# DSS_DISPC register map
Vendor: Texas Instruments
Registers are 32-bit, read-write, no defined reset value unless marked. A register's access mark holds for its fields unless they carry their own. Offsets are as the file gives them; [hi:lo] are bit positions; 'fields as' and 'values as' point back to an identical list.

## DSS_DISPC (part 2 of 2)
0x00 DISPC_REVISION ro — This register contains the IP revision code.
  [7:0] REV — IP revision [[br]][7:4] Major revision [[br]][3:0] Minor revision
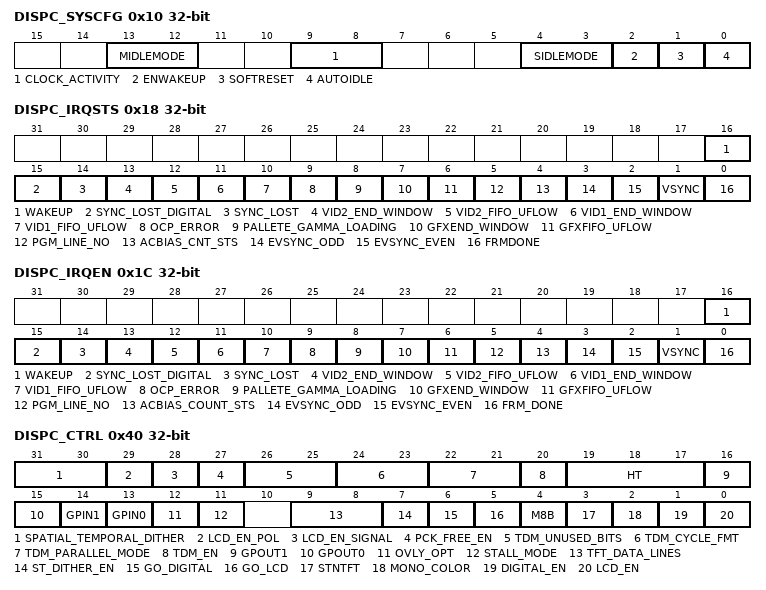
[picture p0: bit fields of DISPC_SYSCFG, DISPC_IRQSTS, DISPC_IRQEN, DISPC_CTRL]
0x10 DISPC_SYSCFG — This register allows the control of various parameters of the interconnect interface
  [13:12] MIDLEMODE — Master interface power management, standby/waitcontrol
    3=en_4_0x3 (3); 2=en_3_0x2 (MStandby is asserted based on the internal activity of the module); 1=en_2_0x1 (MStandby is never asserted); 0=en_1_0x0 (MStandby is asserted only when the module is disabled)
  [9:8] CLOCK_ACTIVITY — Clock activity during wakeup mode period
    3=en_4_0x3 (Interface and functional clocks are maintained during wakeup period); 2=en_3_0x2 (Interface clocks can be switched off and functional clocks are maintained during wakeup period); 1=en_2_0x1 (Functional clocks can be switched off and interface clocks are maintained during wakeup period); 0=en_1_0x0 (interface and functional clocks can be switched off.)
  [4:3] SIDLEMODE — Slave interface power management, idle req/ack control
    3=en_4_0x3 (Reserved); 2=en_3_0x2 (Idle request is acknowledged based on the internal activity of the module); 1=en_2_0x1 (An idle request is never acknowledged); 0=en_1_0x0 (An idle request is acknowledged unconditionally)
  [2] ENWAKEUP — Wakeup feature control
    1=en_2_0x1 (Wakeup is enabled); 0=en_1_0x0 (Wakeup is disabled)
  [1] SOFTRESET — Software reset. [[br]]Set this bit to 1 to trigger a module reset. [[br]]The bit is automatically reset by the hardware. [[br]]During reads, it always returns
    1=en_2_0x1 (The module is reset.); 0=en_1_0x0 (Normal mode)
  [0] AUTOIDLE — Internal interface clock gating strategy
    1=en_2_0x1 (Automatic L3 and L4 interface clock gating strategy is applied based on interface activity); 0=en_1_0x0 (Interface clock is free-running)
0x14 DISPC_SYSSTS ro — This register provides status information about the module, excluding interrupt status information.
  [0] RESETDONE — Internal reset monitoring
    1=en_2_0x1 (Reset complete); 0=en_1_0x0 (Internal module reset is ongoing)
0x18 DISPC_IRQSTS — This register regroups all the status of module internal events that generate an interrupt. A write of 1 to a given bit resets the bit
  [16] WAKEUP
    1=en_4_0x1 (Wakeup is true (pending)); 1=en_3_0x1 (Wakeup status bit reset); 0=en_2_0x0 (Wakeup status bit unchanged); 0=en_1_0x0 (Wakeup is false)
  [15] SYNC_LOST_DIGITAL
    1=en_4_0x1 (SyncLostDigital is true (pending)); 1=en_3_0x1 (SyncLostDigital status bit reset); 0=en_2_0x0 (SyncLostDigital status bit unchanged); 0=en_1_0x0 (SyncLostDigital is false)
  [14] SYNC_LOST
    1=en_4_0x1 (SyncLost is true (pending)); 1=en_3_0x1 (SyncLost status bit reset); 0=en_2_0x0 (SyncLost status bit unchanged); 0=en_1_0x0 (SyncLost is false)
  [13] VID2_END_WINDOW
    1=en_4_0x1 (Vid2EndWindow status bit reset); 1=en_3_0x1 (Vid2EndWindow is true (pending)); 0=en_2_0x0 (Vid2EndWindow status bit unchanged); 0=en_1_0x0 (Vid2EndWindow is false)
  [12] VID2_FIFO_UFLOW — Vid2FIFOUnderflow
    1=en_4_0x1 (Vid2FIFOUnderflow is true (pending)); 1=en_3_0x1 (Vid2FIFOUnderflow status bit reset); 0=en_2_0x0 (Vid2FIFOUnderflow status bit unchanged); 0=en_1_0x0 (Vid2FIFOUnderflow)
  [11] VID1_END_WINDOW
    1=en_4_0x1 (Vid1EndWindow status bit reset); 1=en_3_0x1 (Vid1EndWindow is true (pending).); 0=en_2_0x0 (Vid1EndWindow is false); 0=en_1_0x0 (Vid1EndWindow status bit unchanged)
  [10] VID1_FIFO_UFLOW — Vid1FIFOUnderflow
    1=en_4_0x1 (Vid1FIFOUnderflow status bit reset); 1=en_3_0x1 (Vid1FIFOUnderflow is true (pending).); 0=en_2_0x0 (Vid1FIFOUnderflow status bit unchanged); 0=en_1_0x0 (Vid1FIFOUnderflow is false)
  [9] OCP_ERROR
    1=en_4_0x1 (OCPError status bit reset); 1=en_3_0x1 (OCPError is true (pending).); 0=en_2_0x0 (OCPError is false); 0=en_1_0x0 (OCPError status bit unchanged)
  [8] PALLETE_GAMMA_LOADING — PaletteGammaLoading
    1=en_4_0x1 (PaletteGammaLoading is true (pending)); 1=en_3_0x1 (PaletteGammaLoading status bit reset); 0=en_2_0x0 (PaletteGammaLoading is False); 0=en_1_0x0 (PaletteGammaLoading status bit unchanged)
  [7] GFXEND_WINDOW
    1=en_4_0x1 (GfxEndWindow status bit reset); 1=en_3_0x1 (GfxEndWindow is true (pending).); 0=en_2_0x0 (GfxEndWindow is false.); 0=en_1_0x0 (GfxEndWindow status bit unchanged)
  [6] GFXFIFO_UFLOW — GfxFIFOUnderflow
    1=en_4_0x1 (GfxFIFOUnderflow status bit reset); 1=en_3_0x1 (GfxFIFOUnderflow is true (pending)); 0=en_2_0x0 (GfxFIFOUnderflow is false); 0=en_1_0x0 (GfxFIFOUnderflow status bit unchanged)
  [5] PGM_LINE_NO — ProgrammedLineNumber
    1=en_4_0x1 (ProgrammedLineNumber is true (pending)); 1=en_3_0x1 (ProgrammedLineNumber status bit reset); 0=en_2_0x0 (ProgrammedLineNumber is false); 0=en_1_0x0 (ProgrammedLineNumber status bit unchanged)
  [4] ACBIAS_CNT_STS — ACBiasCountStatus
    1=en_4_0x1 (ACBiasCountStatus is true (pending)); 1=en_3_0x1 (ACBiasCountStatus status bit reset); 0=en_2_0x0 (ACBiasCountStatus is false.); 0=en_1_0x0 (ACBiasCountStatus status bit unchanged)
  [3] EVSYNC_ODD
    1=en_4_0x1 (EVSYNC_ODD is true (pending)); 1=en_3_0x1 (EVSYNC_ODD status bit reset); 0=en_2_0x0 (EVSYNC_ODD status bit unchanged); 0=en_1_0x0 (EVSYNC_ODD is false)
  [2] EVSYNC_EVEN
    1=en_4_0x1 (EVSYNC_EVEN status bit reset); 1=en_3_0x1 (EVSYNC_EVEN is true (pending)); 0=en_2_0x0 (EVSYNC_EVEN is false.); 0=en_1_0x0 (EVSYNC_EVEN status bit unchanged)
  [1] VSYNC
    1=en_4_0x1 (VSYNC is true (pending)); 1=en_3_0x1 (VSYNC status bit reset); 0=en_2_0x0 (VSYNC is false); 0=en_1_0x0 (VSYNC status bit unchanged)
  [0] FRMDONE — FrameDone
    1=en_4_0x1 (FrameDone status bit reset); 1=en_3_0x1 (FrameDone is true (pending).); 0=en_2_0x0 (FrameDone is false); 0=en_1_0x0 (FrameDone status bit unchanged)
0x1C DISPC_IRQEN — This register allows the masking/unmasking of module internal interrupt sources, on an event-by-event basis.
  [16] WAKEUP — Wakeup mask
    1=en_2_0x1 (Wakeup is masked); 0=en_1_0x0 (Wakeup is masked)
  [15] SYNC_LOST_DIGITAL
    1=en_2_0x1 (SyncLostDigital generates an interrupt when it occurs); 0=en_1_0x0 (SyncLostDigital is masked)
  [14] SYNC_LOST
    1=en_2_0x1 (SyncLost is masked); 0=en_1_0x0 (SyncLost is masked)
  [13] VID2_END_WINDOW
    1=en_2_0x1 (Vid2EndWindow generates an interrupt when it occurs); 0=en_1_0x0 (Vid2EndWindow is masked)
  [12] VID2_FIFO_UFLOW — Vid2FIFOUnderflow
    1=en_2_0x1 (Vid2FIFOUnderflow generates an interrupt when it occurs); 0=en_1_0x0 (Vid2FIFOUnderflow is masked)
  [11] VID1_END_WINDOW — EndVid1Window
    1=en_2_0x1 (EndVid1Window is masked); 0=en_1_0x0 (EndVid1Window is masked)
  [10] VID1_FIFO_UFLOW — Vid1FIFOUnderflow
    1=en_2_0x1 (Vid1FIFOUnderflow generates an interrupt when it occurs); 0=en_1_0x0 (Vid1FIFOUnderflow is masked)
  [9] OCP_ERROR
    1=en_2_0x1 (OCPError generates an interrupt when it occurs); 0=en_1_0x0 (OCPError)
  [8] PALLETE_GAMMA_LOADING — PaletteGammaMask
    1=en_2_0x1 (PaletteGammaMask generates an interrupt when it occurs); 0=en_1_0x0 (PaletteGammaMask is masked)
  [7] GFXEND_WINDOW
    1=en_2_0x1 (GfxEndWindow generates an interrupt when it occurs); 0=en_1_0x0 (GfxEndWindow is masked)
  [6] GFXFIFO_UFLOW — GfxFIFOUnderflow
    1=en_2_0x1 (GfxFIFOUnderflow generates an interrupt when it occurs); 0=en_1_0x0 (GfxFIFOUnderflow is masked)
  [5] PGM_LINE_NO — ProgrammedLineNumber
    1=en_2_0x1 (ProgrammedLineNumber generates an interrupt when it occurs); 0=en_1_0x0 (ProgrammedLineNumber is masked.)
  [4] ACBIAS_COUNT_STS — ACBiasCountStatus
    1=en_2_0x1 (ACBiasCountStatus generates an interrupt when it occurs.); 0=en_1_0x0 (ACBiasCountStatus is masked)
  [3] EVSYNC_ODD
    1=en_2_0x1 (EVSYNC_ODD generates an interrupt when it occurs); 0=en_1_0x0 (EVSYNC_ODD is masked)
  [2] EVSYNC_EVEN
    1=en_2_0x1 (EVSYNC_EVEN generates an interrupt when it occurs); 0=en_1_0x0 (EVSYNC_EVEN is masked)
  [1] VSYNC
    1=en_2_0x1 (VSYNC generates an interrupt when it occurs.); 0=en_1_0x0 (VSYNC is masked)
  [0] FRM_DONE — FrameMask
    1=en_2_0x1 (FrameMask generates an interrupt when it occurs); 0=en_1_0x0 (FrameMask is masked)
0x40 DISPC_CTRL access per field — The control register configures the display controller module
  [31:30] SPATIAL_TEMPORAL_DITHER rw — Spatial/Temporal dithering number of frames
    3=en_4_0x3 (Reserved); 2=en_3_0x2 (Spatial and temporal over four frames); 1=en_2_0x1 (Spatial and temporal over two frames); 0=en_1_0x0 (Spatial only)
  [29] LCD_EN_POL rw — LCD Enable Signal Polarity
    1=en_2_0x1 (Active high); 0=en_1_0x0 (Active low)
  [28] LCD_EN_SIGNAL rw — LCD Enable Signal: LCD interface active/inactive
    1=en_2_0x1 (Signal enabled); 0=en_1_0x0 (Signal disabled)
  [27] PCK_FREE_EN rw — Pixel clock free-running enabled/disabled
    1=en_2_0x1 (Clock enabled); 0=en_1_0x0 (Clock disabled)
  [26:25] TDM_UNUSED_BITS rw — State of unused bits (TDM mode only)
    3=en_4_0x3 (Reserved); 2=en_3_0x2 (Unchanged from previous state); 1=en_2_0x1 (High level (1)); 0=en_1_0x0 (Low level (0))
  [24:23] TDM_CYCLE_FMT rw — Cycle format (TDM mode only)
    3=en_4_0x3 (3 cycles for 2 pixels); 2=en_3_0x2 (3 cycles for 1 pixel); 1=en_2_0x1 (2 cycles for 1 pixel); 0=en_1_0x0 (1 cycle for 1 pixel)
  [22:21] TDM_PARALLEL_MODE rw — Output Interface width (TDM mode only)
    3=en_4_0x3 (16-bit parallel output interface selected); 2=en_3_0x2 (12-bit parallel output interface selected); 1=en_2_0x1 (9-bit parallel output interface selected); 0=en_1_0x0 (8-bit parallel output interface selected)
  [20] TDM_EN rw — Enable the multiple cycle format (TDM mode used only for Active Matrix mode with the RFBI enable bit off).
    1=en_2_0x1 (TDM enabled); 0=en_1_0x0 (TDM disabled)
  [19:17] HT rw — Hold Time for digital output WR: EVSYNC Encoded value (from 0 to 7) holds time for digital output. [[br]]The data will be held for (HT + 1) external digital clock periods.
  [16] GPOUT1 rw — General Purpose Output Signal
    1=en_2_0x1 (The GPout1 is set); 0=en_1_0x0 (The GPout1 is reset.)
  [15] GPOUT0 rw — General Purpose Output Signal
    1=en_2_0x1 (The GPout0 is set); 0=en_1_0x0 (The GPout0 is reset)
  [14] GPIN1 ro — General Purpose Input Signal
    1=en_2_0x1 (The GPin1 has been set); 0=en_1_0x0 (The GPin1 has been reset)
  [13] GPIN0 ro — General Purpose Input Signal
    1=en_2_0x1 (The GPin0 has been set); 0=en_1_0x0 (The GPin0 has been reset)
  [12] OVLY_OPT rw — Overlay Optimization (available when graphics format is NOT is 1, 2, and [[br]]4-BPP)
    1=en_2_0x1 (Graphics data below video1 window not fetched from memory.); 0=en_1_0x0 (Graphics data below video1 window fetched from memory or no overlap between graphics and video1 windows)
  [11] STALL_MODE rw — Stall mode for the LCD output
    1=en_2_0x1 (Stall mode selected. The Display Controller sends the data without considering the VSYNC/HSYNC. The LCD output is disabled at the end of the transfer of the frame. The S/W has to re-enable the LCD output to generate a new frame. The stall mode is used in RFBI command modes); 0=en_1_0x0 (Normal mode selected)
  [9:8] TFT_DATA_LINES rw — Number of lines of the LCD interface
    3=en_4_0x3 (24-bit output aligned on the LSB of the pixel data interface); 2=en_3_0x2 (18-bit output aligned on the LSB of the pixel data interface); 1=en_2_0x1 (16-bit output aligned on the LSB of the pixel data interface); 0=en_1_0x0 (12-bit output aligned on the LSB of the pixel data interface)
  [7] ST_DITHER_EN rw — Spatial temporal dithering enable
    1=en_2_0x1 (Spatial/temporal dithering logic enabled); 0=en_1_0x0 (Spatial/temporal dithering logic disabled)
  [6] GO_DIGITAL rw — Digital GO Command
    1=en_2_0x1 (Users have finished programming the shadow registers of the pipeline(s) associated with the digital output and the hardware can update the internal registers at the external VSYNC); 0=en_1_0x0 (The hardware has finished updating the internal shadow registers of the pipeline(s) associated with the digital output using the user values. The hardware resets the bit when the update is completed)
  [5] GO_LCD rw — LCD GO Command
    1=en_2_0x1 (Users have finished programming the shadow registers of the pipeline(s) associated with the LCD output and the hardware can update the internal registers at the VFP start period.); 0=en_1_0x0 (The hardware has finished updating the internal shadow registers of the pipeline(s) connected to the LCD output using the user values. The hardware resets the bit when the update is completed)
  [4] M8B rw — Mono [[br]]8-bit mode
    1=en_2_0x1 (Pixel data [7:0] is used to output eight pixel values to the panel each pixel clock transition (only in Passive Mono 8-bit mode)); 0=en_1_0x0 (Pixel data [3:0] is used to output four pixel values to the panel at each pixel clock transition (only in Passive Mono 8-bit mode))
  [3] STNTFT rw — LCD display type
    1=en_2_0x1 (Active Matrix display operation enabled. Passive Matrix Dither logic and output FIFO bypassed); 0=en_1_0x0 (Passive or Passive Matrix display operation enabled. Passive Matrix dither logic enabled)
  [2] MONO_COLOR rw — Monochrome/Color
    1=en_2_0x1 (Monochrome operation enabled (Passive Matrix mode only)); 0=en_1_0x0 (Color operation enabled (Passive Matrix mode only))
  [1] DIGITAL_EN rw — Digital enable
    1=en_2_0x1 (Digital output enabled); 0=en_1_0x0 (Digital output disabled (at the end of the current field if interlace output when the bit is reset))
  [0] LCD_EN rw — LCD enable
    1=en_2_0x1 (LCD output disabled (at the end of the frame when the bit is reset)); 0=en_1_0x0 (LCD output disabled (at the end of the frame when the bit is reset))
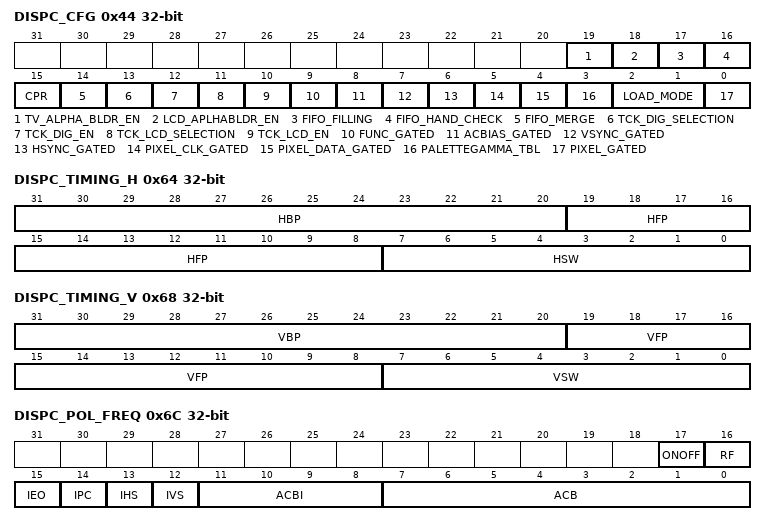
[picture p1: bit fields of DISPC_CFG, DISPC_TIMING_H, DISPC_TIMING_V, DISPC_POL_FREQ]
0x44 DISPC_CFG — This control register configures the display controller module. Shadow register, updated on VFP start period or EVSYNC
  [19] TV_ALPHA_BLDR_EN — Selects the alpha blender (TV output)
    1=en_2_0x1 (The alpha blender is enabled); 0=en_1_0x0 (Alpha blender is disabled)
  [18] LCD_APLHABLDR_EN — Selects the alpha blender (LCD output)
    1=en_2_0x1 (The alpha blender is enabled); 0=en_1_0x0 (Alpha blender is disabled.)
  [17] FIFO_FILLING — Controls if the FIFO are refilled only when the LOW threshold is reached or if all FIFO are refilled when at least one of them reaches the LOW threshold.
    1=en_2_0x1 (All FIFOs are refilled up to high threshold when at least one of them reaches the LOW threshold. (only active FIFOs should be considered and when reaching the end of the frame the FIFO goes to empty condition so no need to fill it again)); 0=en_1_0x0 (Each FIFO is refilled when it reaches LOW threshold)
  [16] FIFO_HAND_CHECK — Controls the handshake between FIFO and RFBI STALL to prevent from underflow. [[br]]The bit should be set to 0 when the module is not in STALL mode
    1=en_2_0x1 (The STALL signal from RFBI is used in combination with the FIFO fullness information to provide data to the RFBI module only when it does not generated FIFO underflow.); 0=en_1_0x0 (Only the STALL signal from RFBI is used regardless of the FIFO fullness information to provide data to the RFBI module)
  [15] CPR — Color phase rotation control wr: VFP
    1=en_2_0x1 (Color phase rotation enabled); 0=en_1_0x0 (Color phase rotation disabled)
  [14] FIFO_MERGE — FIFO merge control
    1=en_2_0x1 (FIFO merge enabled All the FIFOS are merged into a single one to be used by the single active pipeline); 0=en_1_0x0 (FIFO merge disabled Each FIFO is dedicated to one pipeline)
  [13] TCK_DIG_SELECTION — Transparency color key selection (digital output)
    1=en_2_0x1 (Video source transparency color key selected in normal mode); 0=en_1_0x0 (Graphics destination transparency color key selected in normal mode or graphics source transparency color key selected in alpha mode)
  [12] TCK_DIG_EN — Transparency color key enabled (digital output)
    1=en_2_0x1 (Enable the transparency color key for digital output); 0=en_1_0x0 (Disable the transparency color key for digital output)
  [11] TCK_LCD_SELECTION — Transparency color key selection (LCD output)
    values as TCK_DIG_SELECTION
  [10] TCK_LCD_EN — Transparency color key enabled (LCD output)
    1=en_2_0x1 (Enable the transparency color key for the LCD); 0=en_1_0x0 (Disable the transparency color key for the LCD)
  [9] FUNC_GATED — Functional clocks gated enabled
    1=en_2_0x1 (Functional clocks gated enabled); 0=en_1_0x0 (Functional clocks gated disabled)
  [8] ACBIAS_GATED — ACBias Gated Enabled
    1=en_2_0x1 (ACBias Gated Enabled); 0=en_1_0x0 (ACBias Gated Disabled)
  [7] VSYNC_GATED — VSYNC Gated Enabled
    1=en_2_0x1 (VSYNC Gated Enabled); 0=en_1_0x0 (VSYNC Gated Disabled)
  [6] HSYNC_GATED — HSYNC Gated Enabled
    1=en_2_0x1 (HSYNC Gated Enabled); 0=en_1_0x0 (HSYNC Gated Disabled)
  [5] PIXEL_CLK_GATED — Pixel Clock Gated Enabled
    1=en_2_0x1 (Pixel Clock Gated Enabled); 0=en_1_0x0 (Pixel Clock Gated Disabled)
  [4] PIXEL_DATA_GATED — Pixel Data Gated Enabled
    1=en_2_0x1 (Pixel Data Gated Enabled); 0=en_1_0x0 (Pixel Data Gated Disabled)
  [3] PALETTEGAMMA_TBL — Palette/Gamma Table selection
    1=en_2_0x1 (LUT used as gamma table (only if graphics format is NOT BITMAP1, 2, 4, and 8 or no graphics window present)); 0=en_1_0x0 (LUT used as palette (only if graphics format is BITMAP1, 2, 4, and 8))
  [2:1] LOAD_MODE — Loading Mode for the Palette/Gamma Table
    3=en_4_0x3 (Palette/Gamma Table and frame data loaded on first frame then switch to 10 (H/W)); 2=en_3_0x2 (Frame data only loaded every frame); 1=en_2_0x1 (Palette/Gamma Table to be loaded. Users set the bit when the palette/gamma table has to be loaded. H/W resets the bit when table has been loaded. (DISPC_GFX_ATTRIBUTES. GfxEnable has to be set to 1)); 0=en_1_0x0 (Palette/Gamma Table and data are loaded every frame)
  [0] PIXEL_GATED — Pixel Gated Enable (only for Active Matrix Display)
    1=en_2_0x1 (Pixel clock only toggles when there is valid data to display. (only in Active Matrix mode)); 0=en_1_0x0 (Pixel Gated Enable (only for Active Matrix Display))
0x4C DISPC_DEFAULT_COLOR_0 access not given
0x50 DISPC_DEFAULT_COLOR_1 access not given
0x54 DISPC_TRANS_COLOR_0 access not given
0x58 DISPC_TRANS_COLOR_1 access not given
0x5C DISPC_LINE_STS ro — The control register indicates the current LCD panel display line number
  [10:0] LINE_NUMBER — Current LCD panel line number Current display line number. [[br]]The first active line has the value 0. [[br]]During blanking lines the line number is not incremented
0x60 DISPC_LINE_NUMBER — The control register indicates the LCD panel display line number for the interrupt and the DMA request. Shadow register, updated on VFP start period
  [10:0] LINE_NUMBER — LCD panel line number programming LCD line number defines the line on which the programmable interrupt is generated and the DMA request occurs
0x64 DISPC_TIMING_H — The register configures the timing logic for the HSYNC signal. Shadow register, updated on VFP start period
  [31:20] HBP — Horizontal Back Porch. [[br]]Encoded value (from 1 to 4096) to specify the number of pixel clock periods to add to the beginning of a line transmission before the first set of pixels is output to the display (program to value minus 1)
  [19:8] HFP — Horizontal front porch. [[br]]Encoded value (from 1 to 4096) to specify the number of pixel clock periods to add to the end of a line transmission before line clock is asserted (program to value minus 1)
  [7:0] HSW — Horizontal synchronization pulse width Encoded value (from 1 to 256) to specify the number of pixel clock periods to pulse the line clock at the end of each line (program to value minus 1).
0x68 DISPC_TIMING_V — The register configures the timing logic for the VSYNC signal. Shadow register, updated on VFP start period
  [31:20] VBP — Vertical back porch Encoded value (from 0 to 4095) to specify the number of line clock periods to add to the beginning of a frame before the first set of pixels is output to the display
  [19:8] VFP — Vertical front porch Encoded value (from 0 to 4095) to specify the number of line clock periods to add to the end of each frame
  [7:0] VSW — Vertical synchronization pulse width In active mode, encoded value (from 1 to 256) to specify the number of line clock periods (program to value minus one) to pulse the frame clock (VSYNC) pin at the end of each frame after the end of frame wait (VFP) period elapses. [[br]]Frame clock uses as VSYNC signal in active mode. [[br]]In passive mode, encoded value (from 1 to 256) to specify the number of extra line clock periods (program to value minus one) to insert after the vertical front porch (VFP) period has elapsed.
0x6C DISPC_POL_FREQ — The register configures the signal configuration. Shadow register, updated on VFP start period
  [17] ONOFF — HSYNC/VSYNC Pixel clock Control On/Off
    1=en_2_0x1 (HSYNC and VSYNC are driven according to bit 16); 0=en_1_0x0 (HSYNC and VSYNC are driven on opposite edges of pixel clock than pixel data)
  [16] RF — Program HSYNC/VSYNC Rise or Fall
    1=en_2_0x1 (HSYNC and VSYNC are driven on the rising edge of pixel clock (if bit 17 set to 1)); 0=en_1_0x0 (HSYNC and VSYNC are driven on falling edge of pixel clock (if bit 17 set to 1))
  [15] IEO — Invert output enable
    1=en_2_0x1 (Ac-bias is active low (active display mode)); 0=en_1_0x0 (Ac-bias is active high (active display mode))
  [14] IPC — Invert pixel clock
    1=en_2_0x1 (Data is driven on the LCD data lines on the falling-edge of the pixel clock); 0=en_1_0x0 (Data is driven on the LCD data lines on the rising-edge of the pixel clock)
  [13] IHS — Invert HSYNC
    1=en_2_0x1 (Line clock pin is active low and inactive high); 0=en_1_0x0 (Line clock pin is active high and inactive low)
  [12] IVS — Invert VSYNC
    1=en_2_0x1 (Frame clock pin is active low and inactive high); 0=en_1_0x0 (Frame clock pin is active high and inactive low)
  [11:8] ACBI — AC-bias pin transitions per interrupt Value (from 0 to 15) used to specify the number of AC Bias pin transitions
  [7:0] ACB — AC-bias pin frequency Value (from 0 to 255) used to specify the number of line clocks to count before transitioning the ac-bias pin. [[br]]This pin is used to periodically invert the polarity of the power supply to prevent DC charge build-up within the display.
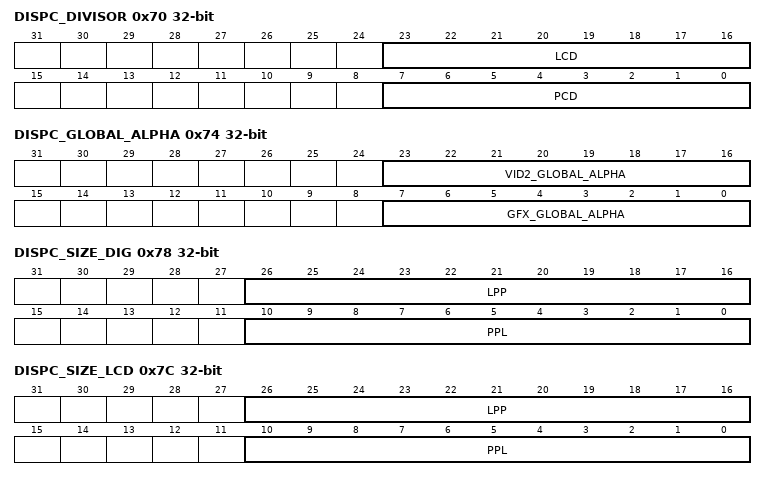
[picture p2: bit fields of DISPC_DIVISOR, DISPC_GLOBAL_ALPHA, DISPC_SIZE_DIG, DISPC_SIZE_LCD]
0x70 DISPC_DIVISOR — The register configures the divisors. Shadow register, updated on VFP start period
  [23:16] LCD — Display Controller Logic Clock Divisor Value (from 1 to 255) to specify the frequency of the display controller logic clock based on the function clock. [[br]]The value 0 is invalid.
  [7:0] PCD — Pixel Clock Divisor Value (from 1 to 255) to specify the frequency of the pixel clock based on the Logic clock which is the functional clock divided by LCD. [[br]]The values 0 and 1 are invalid.
0x74 DISPC_GLOBAL_ALPHA — The register defines the global alpha value for the graphics and video 2 pipelines. Shadow register, updated on VFP start period or EVSYNC for each bit field depending on the association of the each pipeline with the LCD or TV output.
  [23:16] VID2_GLOBAL_ALPHA — Global alpha value from 0 to 255. [[br]]0 corresponds to fully transparent and 255 to fully opaque
  [7:0] GFX_GLOBAL_ALPHA — Global alpha value from 0 to 255. [[br]]0 corresponds to fully transparent and 255 to fully opaque
0x78 DISPC_SIZE_DIG — The register configures the size of the digital output field (interlace), frame (progressive) (horizontal and vertical). Shadow register, updated on EVSYNC
  [26:16] LPP — Lines per panel Encoded value (from 1 to 2048) to specify the number of lines per panel (program to value minus one)
  [10:0] PPL — Pixels per line Encoded value (from 1 to 2048) to specify the number of pixels contained within each line on the display (program to value minus one)
0x7C DISPC_SIZE_LCD — The register configures the panel size (horizontal and vertical). Shadow register, updated on VFP start period
  [26:16] LPP — Lines per panel Encoded value (from 1 to 2048) to specify the number of lines per panel (program to value minus one)
  [10:0] PPL — Pixels per line Encoded value (from 1 to 2048) to specify the number of pixels contains within each line on the display (program to value minus one). [[br]]When running in normal mode (stall mode is bypassed by setting DSS.DISPC_CONTROL[11] STALLMODE =0) the line width must be set to a value multiple of 8 pixels (ex: PPL=0x7)
0x80 DISPC_GFX_BA_0 access not given
0x84 DISPC_GFX_BA_1 access not given
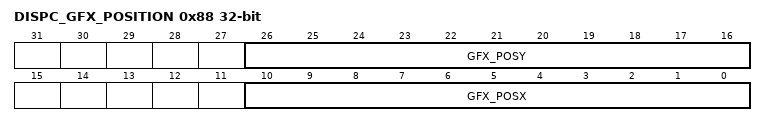
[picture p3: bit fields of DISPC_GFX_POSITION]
0x88 DISPC_GFX_POSITION — The register configures the position of the graphics window. Shadow register, updated on VFP start period or EVSYNC.
  [26:16] GFX_POSY — Y position of the graphics window. [[br]]Encoded value (from 0 to 2047) to specify the Y position of the graphics window on the screen. [[br]]The line at the top has the Y-position 0.
  [10:0] GFX_POSX — X position of the graphics window. [[br]]Encoded value (from 0 to 2047) to specify the X position of the graphics window on the screen. [[br]]The first pixel on the left of the screen has the X-position 0.
